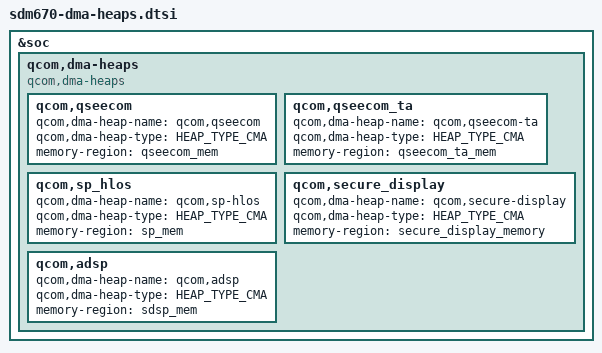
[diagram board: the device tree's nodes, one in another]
#include <dt-bindings/arm/msm/qcom_dma_heap_dt_constants.h>

&soc {
	qcom,dma-heaps {
		compatible = "qcom,dma-heaps";

		qcom,qseecom { /* QSEECOM HEAP */
			qcom,dma-heap-name = "qcom,qseecom";
			qcom,dma-heap-type = <HEAP_TYPE_CMA>;
			memory-region = <&qseecom_mem>;
		};

		qcom,qseecom_ta { /* QSEECOM TA HEAP */
			qcom,dma-heap-name = "qcom,qseecom-ta";
			qcom,dma-heap-type = <HEAP_TYPE_CMA>;
			memory-region = <&qseecom_ta_mem>;
		};

		qcom,sp_hlos { /* SPSS HEAP */
			qcom,dma-heap-name = "qcom,sp-hlos";
			qcom,dma-heap-type = <HEAP_TYPE_CMA>;
			memory-region = <&sp_mem>;
		};

		qcom,secure_display { /* SECURE DISPLAY HEAP */
			qcom,dma-heap-name = "qcom,secure-display";
			qcom,dma-heap-type = <HEAP_TYPE_CMA>;
			memory-region = <&secure_display_memory>;
		};

		qcom,adsp { /* ADSP HEAP */
			qcom,dma-heap-name = "qcom,adsp";
			qcom,dma-heap-type = <HEAP_TYPE_CMA>;
			memory-region = <&sdsp_mem>;
		};
	};
};
